AUTOSAR XML (schema 00049)
standard types defined: boolean, float32, sint16, uint16, uint8, boolean_CompuMethod, boolean_DataConstr, float32_DataConstr, sint16_DataConstr, uint16_DataConstr, uint8_DataConstr
package /ComponentTypes
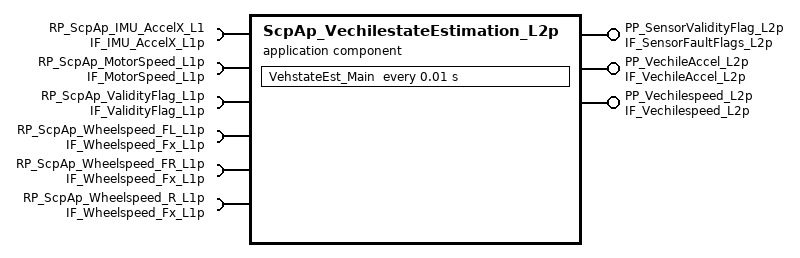
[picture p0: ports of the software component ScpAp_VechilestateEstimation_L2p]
  application sw component type ScpAp_VechilestateEstimation_L2p
    provide port PP_SensorValidityFlag_L2p: nonqueued-sender-com-spec{data-element=IF_SensorFaultFlags_L2p, init-value=fields=[MotorRPM_Fault:0, Accel_Fault:0, WSS_Fault:0, VechSpeedEst_Fault:0]}, provided-interface=IF_SensorFaultFlags_L2p
    provide port PP_VechileAccel_L2p: nonqueued-sender-com-spec{data-element=IF_VechileAccel_L2p, init-value=0}, provided-interface=IF_VechileAccel_L2p
    provide port PP_Vechilespeed_L2p: nonqueued-sender-com-spec{data-element=IF_Vechilespeed_L2p, init-value=0}, provided-interface=IF_Vechilespeed_L2p
    6 x require port:
      RP_ScpAp_IMU_AccelX_L1: nonqueued-receiver-com-spec{data-element=IF_IMU_AccelX_L1p, filter=data-filter-type=ALWAYS}, required-interface=IF_IMU_AccelX_L1p
      RP_ScpAp_MotorSpeed_L1p: nonqueued-receiver-com-spec{data-element=IF_MotorSpeed_L1p, filter=data-filter-type=ALWAYS, init-value=ComSpec8213ca7e_f94256d2655c1c70:0}, required-interface=IF_MotorSpeed_L1p
      RP_ScpAp_ValidityFlag_L1p: nonqueued-receiver-com-spec{data-element=IF_ValidityFlag_L1p, filter=data-filter-type=ALWAYS, init-value=fields=[Motor_RPM_Valid_Flg:0, WSS_FR_Valid_Flg:0, WSS_FL_Valid_Flg:0, WSS_R_Valid_Flg:0, IMU_AccelX_Valid_Flg:0, SensorStuck_Valid_Flg:0]}, required-interface=IF_ValidityFlag_L1p
      RP_ScpAp_Wheelspeed_FL_L1p: nonqueued-receiver-com-spec{data-element=IF_Wheelspeed_Fx_L1p, filter=data-filter-type=ALWAYS, init-value=0}, required-interface=IF_Wheelspeed_Fx_L1p
      RP_ScpAp_Wheelspeed_FR_L1p: nonqueued-receiver-com-spec{data-element=IF_Wheelspeed_Fx_L1p, filter=data-filter-type=ALWAYS, init-value=0}, required-interface=IF_Wheelspeed_Fx_L1p
      RP_ScpAp_Wheelspeed_R_L1p: nonqueued-receiver-com-spec{data-element=IF_Wheelspeed_Fx_L1p, filter=data-filter-type=ALWAYS, init-value=0}, required-interface=IF_Wheelspeed_Fx_L1p
    behavior ScpAp_VechilestateEstimation_L2p_InternalBehavior: handle-termination-and-restart=NO-SUPPORT
      timing event TMT_VehstateEst_Main: start-on-event=VehstateEst_Main, period=0.01
      runnable VehstateEst_Main
        data-receive-point-by-arguments:
          6 x access:
            REC_RP_ScpAp_IMU_AccelX_L1_Element: accessed-variable=RP_ScpAp_IMU_AccelX_L1.IF_IMU_AccelX_L1p
            REC_RP_ScpAp_MotorSpeed_L1p_IF_MotorSpeed_L1p: accessed-variable=RP_ScpAp_MotorSpeed_L1p.IF_MotorSpeed_L1p
            REC_RP_ScpAp_ValidityFlag_L1p_IF_ValidityFlag_L1p: accessed-variable=RP_ScpAp_ValidityFlag_L1p.IF_ValidityFlag_L1p
            REC_RP_ScpAp_Wheelspeed_FL_L1p_Element: accessed-variable=RP_ScpAp_Wheelspeed_FL_L1p.IF_Wheelspeed_Fx_L1p
            REC_RP_ScpAp_Wheelspeed_FR_L1p_IF_Wheelspeed_Fx_L1p: accessed-variable=RP_ScpAp_Wheelspeed_FR_L1p.IF_Wheelspeed_Fx_L1p
            REC_RP_ScpAp_Wheelspeed_R_L1p_IF_Wheelspeed_Fx_L1p: accessed-variable=RP_ScpAp_Wheelspeed_R_L1p.IF_Wheelspeed_Fx_L1p
        data-send-points:
          access SEND_PP_SensorValidityFlag_L2p_IF_SensorFaultFlags_L2p: accessed-variable=PP_SensorValidityFlag_L2p.IF_SensorFaultFlags_L2p
          access SEND_PP_VechileAccel_L2p_IF_VechileAccel_L2p: accessed-variable=PP_VechileAccel_L2p.IF_VechileAccel_L2p
          access SEND_PP_Vechilespeed_L2p_IF_Vechilespeed_L2p: accessed-variable=PP_Vechilespeed_L2p.IF_Vechilespeed_L2p
  swc implementation ScpAp_VechilestateEstimation_L2p_Implementation: behavior=ScpAp_VechilestateEstimation_L2p_InternalBehavior
    code-descriptors:
      code Default: artifact-descriptors=autosar-engineering-object=category=SWSRC
package /DataTypes
  impl type IF_SensorFaultFlgs_L2p_IDT: category=STRUCTURE, sw-calibration-access=READ-ONLY, type-emitter=RTE
    4 x element, all with category=VALUE, base-type=boolean, sw-calibration-access=READ-ONLY:
      MotorRPM_Fault
      Accel_Fault
      WSS_Fault
      VechSpeedEst_Fault
  impl type IF_ValidityFlag_L1p_IDT: category=STRUCTURE, sw-calibration-access=READ-ONLY, type-emitter=RTE
    6 x element, all with category=TYPE_REFERENCE, base-type=boolean, sw-calibration-access=READ-ONLY, implementation-data-type=boolean:
      Motor_RPM_Valid_Flg
      WSS_FR_Valid_Flg
      WSS_FL_Valid_Flg
      WSS_R_Valid_Flg
      IMU_AccelX_Valid_Flg
      SensorStuck_Valid_Flg
package /PortInterfaces
  7 x sender receiver interface:
    IF_IMU_AccelX_L1p: invalidation-policy{data-element=IF_IMU_AccelX_L1p, handle-invalid=DONT-INVALIDATE}
      data IF_IMU_AccelX_L1p: category=VALUE, sw-calibration-access=READ-ONLY, type=float32
    IF_MotorSpeed_L1p: invalidation-policy{data-element=IF_MotorSpeed_L1p, handle-invalid=DONT-INVALIDATE}
      data IF_MotorSpeed_L1p: category=VALUE, sw-calibration-access=READ-ONLY, type=uint8
    IF_SensorFaultFlags_L2p: invalidation-policy{data-element=IF_SensorFaultFlags_L2p, handle-invalid=DONT-INVALIDATE}
      data IF_SensorFaultFlags_L2p: type=IF_SensorFaultFlgs_L2p_IDT
    IF_ValidityFlag_L1p: invalidation-policy{data-element=IF_ValidityFlag_L1p, handle-invalid=DONT-INVALIDATE}
      data IF_ValidityFlag_L1p: category=STRUCTURE, sw-calibration-access=READ-ONLY, type=IF_ValidityFlag_L1p_IDT
    IF_VechileAccel_L2p: invalidation-policy{data-element=IF_VechileAccel_L2p, handle-invalid=DONT-INVALIDATE}
      data IF_VechileAccel_L2p: type=sint16
    IF_Vechilespeed_L2p: invalidation-policy{data-element=IF_Vechilespeed_L2p, handle-invalid=DONT-INVALIDATE}
      data IF_Vechilespeed_L2p: type=uint16
    IF_Wheelspeed_Fx_L1p: invalidation-policy{data-element=IF_Wheelspeed_Fx_L1p, handle-invalid=DONT-INVALIDATE}
      data IF_Wheelspeed_Fx_L1p: category=VALUE, sw-calibration-access=READ-ONLY, type=uint16
